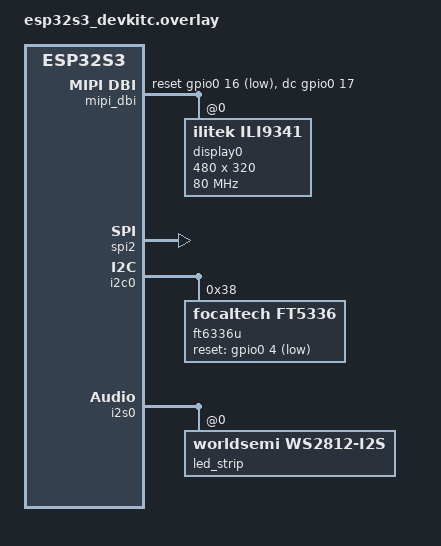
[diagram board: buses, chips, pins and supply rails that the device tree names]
/* Auto-generated by @typecad/framework-zephyr from cuttlefish.config.ts. */
/* Enables peripherals the program uses. West merges this over the board DT. */

&dma {
    status = "okay";
};

&spi2 {
    status = "okay";
    cs-gpios = <&gpio0 5 GPIO_ACTIVE_LOW>;
    dma-enabled;
    dmas = <&dma 0>, <&dma 1>;
    dma-names = "rx", "tx";
};

/ {
    mipi_dbi: mipi-dbi {
        compatible = "zephyr,mipi-dbi-spi";
        spi-dev = <&spi2>;
        dc-gpios = <&gpio0 17 GPIO_ACTIVE_HIGH>;
        reset-gpios = <&gpio0 16 GPIO_ACTIVE_LOW>;
        write-only;
        #address-cells = <1>;
        #size-cells = <0>;
        display0: display@0 {
            compatible = "ilitek,ili9341";
            reg = <0>;
            mipi-max-frequency = <80000000>;
            mipi-mode = "MIPI_DBI_MODE_SPI_4WIRE";
            pixel-format = <0>;
            width = <480>;
            height = <320>;
            rotation = <90>;
        };
    };
};

&pinctrl {
    i2c0_touch: i2c0_touch {
        group1 {
            pinmux = <I2C0_SDA_GPIO8>, <I2C0_SCL_GPIO9>;
            bias-pull-up;
            drive-open-drain;
        };
    };
};

&i2c0 {
    status = "okay";
    pinctrl-0 = <&i2c0_touch>;
    pinctrl-names = "default";
    ft6336u: ft6336u@38 {
        compatible = "focaltech,ft5336";
        reg = <0x38>;
        reset-gpios = <&gpio0 4 GPIO_ACTIVE_LOW>;
    };
};

&psram0 {
    status = "okay";
    size = <(DT_SIZE_M(8))>;
};

/*
 * Onboard WS2812 RGB LED — ESP32-S3 DevKitC, GPIO48, I2S backend.
 *
 * Adapted from Zephyr's in-tree sample overlay for this exact board:
 *   samples/drivers/led/led_strip/boards/esp32s3_devkitc_procpu.overlay
 *   Copyright (c) 2024-2025 Espressif Systems (Shanghai) Co., Ltd.
 *   SPDX-License-Identifier: Apache-2.0
 *
 * Appended to the generated boards/<board>.overlay when the library's
 * __tc_rgbled include token appears in the emitted sources. color-mapping
 * uses raw LED_COLOR_ID values (GREEN=2, RED=1, BLUE=3 — the WS2812 GRB
 * wire order) to keep the fragment include-free.
 */

/ {
	aliases {
		led-strip = &led_strip;
	};
};

&i2s0_default {
	group1 {
		pinmux = <I2S0_O_SD_GPIO48>;
	};
};

i2s_led: &i2s0 {
	status = "okay";

	dmas = <&dma 3>;
	dma-names = "tx";

	led_strip: ws2812@0 {
		compatible = "worldsemi,ws2812-i2s";

		reg = <0>;
		chain-length = <1>;
		color-mapping = <2 1 3>; /* GRB: LED_COLOR_ID_GREEN, _RED, _BLUE */
		reset-delay = <500>;
	};
};

&dma {
	status = "okay";
};
